# STM32H730 register map
File version: 1.8
CPU: CM7 r0p1, little endian, MPU, FPU, 4 interrupt priority bits
Registers are 32-bit, read-write, reset 0x0 unless marked. A register's access mark holds for its fields unless they carry their own. Offsets are from the block's base; [hi:lo] are bit positions; {n}, {i} and the like mark numbered series; 'fields as' and 'values as' point back to an identical list.

## OTFDEC1 — OTFDEC address block description
Base 0x5200B800
Same registers: OTFDEC2 0x5200BC00
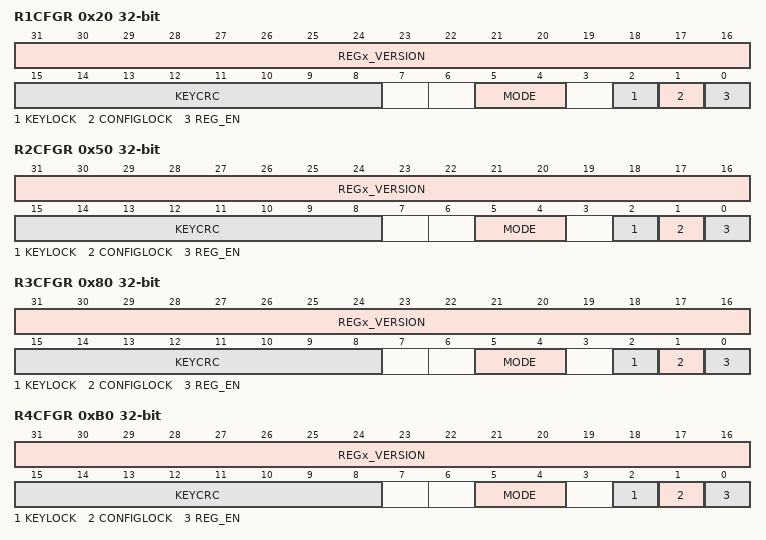
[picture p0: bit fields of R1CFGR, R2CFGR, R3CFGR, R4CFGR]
0x20 R1CFGR access per field — OTFDEC region 1 configuration register
  [31:16] REGx_VERSION rw — region firmware version This 16-bit bitfield must be correctly initialized before the region corresponding REG_EN bit is set in the RxCFGR register.
  [15:8] KEYCRC ro — region key 8-bit CRC When KEYLOCK=0, KEYCRC bitfield is automatically computed by hardware while loading the key of this region in this exact sequence: KEYR0 then KEYR1 then KEYR2 then finally KEYR3 (all written once). A new computation starts as soon as a new valid sequence is initiated, and KEYCRC is read as zero until a valid sequence is completed. When KEYLOCK=1, KEYCRC remains unchanged until the next reset. CRC computation is an 8-bit checksum using the standard CRC-8-CCITT algorithm X8 + X2 + X + 1 (according the convention). Source code is available in this manual. This field is read only. Note: CRC information is updated only after the last bit of the key has been written.
  [5:4] MODE rw — operating mode This bitfield selects the OTFDEC operating mode for this region: When MODE is not equal to 11 the standard AES encryption mode is activated. When either of the MODE bits are changed the region's key and associated CRC are zeroed.
  [2] KEYLOCK rw — region key lock This bitfield is set once, i.e. if this bit is set it can only be reset to '0' if the OTFDEC is reset.
  [1] CONFIGLOCK rw — region config lock This bit-field is set once, i.e. if this bit is set it can only be reset to '0' if OTFDEC is reset. Setting this bit forces KEYLOCK bit to '1'.
  [0] REG_EN rw — region on-the-fly decryption enable Note: When this bit is set region context (version, key, nonce) must be valid or garbage will be decrypted.
0x24 R1STARTADDR — OTFDEC region 1 start address register
  [31:0] REGx_START_ADDR — Region AXI start address This register must be written before the region corresponding REG_EN bit in the RxCFGR register is set. Writing this register while the region CONFIGLOCK bit in the RxCFGR register is set will be discarded. Note: When determining the region the first 12 bits (LSB) and the last 4 bits (MSB) are ignored. When this register is accessed in read the 4 MSB bits and the 12 LSB bits return zero.
0x28 R1ENDADDR reset 0xFFF — OTFDEC region 1 end address register
  [31:0] REGx_END_ADDR — Region AXI end address This register must be written before the region corresponding REG_EN bit in the RxCFGR register is set, and RxENDADDR must be strictly greater than RxSTARTADDR to be valid. Writing this register while the region CONFIGLOCK bit in the RxCFGR register is set will be discarded. Note: When determining the region the first 12 bits (LSB) and the last 4 bits (MSB) are ignored. When this register is accessed in read the 4 MSB bits returns zeros and the 12 LSB bits return ones.
0x2C R1NONCER0 — OTFDEC region 1 nonce register 0
  [31:0] REGx_NONCE — Region nonce, bits [31:0] This register must be written before the region corresponding REG_EN bit in the RxCFGR register is set. Writing this register while the region CONFIGLOCK bit in the RxCFGR register is set will be discarded.
{0x0+0x30*i} R{i}NONCER1 (i=1..4) — OTFDEC region {i} nonce register 1
  [31:0] REGx_NONCE — Region nonce, bits [63:32] Refer to the OTFDEC_RxNONCER0 register for description of the NONCE[63:0] bitfield.
{0x4+0x30*i} R{i}KEYR0 wo (i=1..4) — OTFDEC region {i} key register 0
  [31:0] REGx_KEY — Region key, bits [31:0] This register must be written before the region corresponding REG_EN bit in the RxCFGR register is set. Reading this register returns a zero value. Writing this register while the region CONFIGLOCK or KEYLOCK bit is set in the RxCFGR register will be discarded. Note: When application successfully changes MODE bits in RxCFGR register RxKEYR registers and associated KEYCRC are erased.
{0x8+0x30*i} R{i}KEYR1 wo (i=1..4) — OTFDEC region {i} key register 1
  [31:0] REGx_KEY — Region key, bits [63:32] Refer to the OTFDEC_RxKEYR0 register for description of the KEY[127:0] bitfield.
{0xC+0x30*i} R{i}KEYR2 wo (i=1..4) — OTFDEC region {i} key register 2
  [31:0] REGx_KEY — Region key, bits [95:64] Refer to the OTFDEC_RxKEYR0 register for description of the KEY[127:0] bitfield.
{0x10+0x30*i} R{i}KEYR3 wo (i=1..4) — OTFDEC region {i} key register 3
  [31:0] REGx_KEY — Region key, bits [127:96] Refer to the OTFDEC_RxKEYR0 register for description of the KEY[127:0] bitfield.
0x50 R2CFGR access per field — OTFDEC region 2 configuration register
  fields as R1CFGR
0x54 R2STARTADDR — OTFDEC region 2 start address register
  fields as R1STARTADDR
0x58 R2ENDADDR reset 0xFFF — OTFDEC region 2 end address register
  fields as R1ENDADDR
0x5C R2NONCER0 — OTFDEC region 2 nonce register 0
  fields as R1NONCER0
0x80 R3CFGR access per field — OTFDEC region 3 configuration register
  fields as R1CFGR
0x84 R3STARTADDR — OTFDEC region 3 start address register
  fields as R1STARTADDR
0x88 R3ENDADDR reset 0xFFF — OTFDEC region 3 end address register
  fields as R1ENDADDR
0x8C R3NONCER0 — OTFDEC region 3 nonce register 0
  fields as R1NONCER0
0xB0 R4CFGR access per field — OTFDEC region 4 configuration register
  fields as R1CFGR
0xB4 R4STARTADDR — OTFDEC region 4 start address register
  fields as R1STARTADDR
0xB8 R4ENDADDR reset 0xFFF — OTFDEC region 4 end address register
  fields as R1ENDADDR
0xBC R4NONCER0 — OTFDEC region 4 nonce register 0
  fields as R1NONCER0
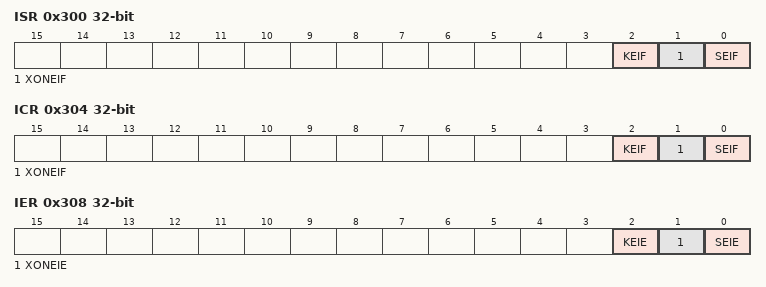
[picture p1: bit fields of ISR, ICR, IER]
0x300 ISR ro — OTFDEC interrupt status register
  [2] KEIF — Key Error Interrupt Flag status This bit is set by hardware and read only by application. Bit is set when a read access occurs on any encrypted region following the reset of the key registers by an abort event (tamper detection, unauthorized debugger connection, untrusted boot, RDP level regression). Bit is cleared when application sets in OTFDEC_ICR the corresponding bit to '1'. After KEIF is set any subsequent read to any enabled encrypted region returns a zeroed value. This state remains until OTFDEC keys are initialized again.
  [1] XONEIF — Execute-only execute-Never Error Interrupt Flag status This bit is set by hardware and read only by application. Bit is set when a read access and not an instruction fetch is detected on any encrypted region with MODE bits set to 00 or 11. It is also set when an instruction fetch and not a read access is detected on any encrypted region with MODE bits set to 01. Bit is cleared when application sets in OTFDEC_ICR the corresponding bit to '1'.
  [0] SEIF — Security Error Interrupt Flag status This bit is set by hardware and read only by application. Bit is set when at least one security error has been detected (illegal access to keys, illegal write on locked configuration). Bit is cleared when application sets in OTFDEC_ICR the corresponding bit to '1'.
0x304 ICR wo — OTFDEC interrupt clear register
  [2] KEIF — Key Error Interrupt Flag clear This bit is written by application, and always reads as 0. Note: Clearing KEIF does not solve the source of the problem (bad key registers). To be able to read or execute again any encrypted region, OTFDEC key registers must properly initialized, again.
  [1] XONEIF — Execute-only execute-Never Error Interrupt Flag clear This bit is written by application, and always reads as 0.
  [0] SEIF — Security Error Interrupt Flag clear This bit is written by application, and always reads as 0.
0x308 IER — OTFDEC interrupt enable register
  [2] KEIE — Key Error Interrupt Enable This bit is read and written by application. It controls the OTFDEC interrupt generation when KEIF flag status is set.
  [1] XONEIE — Execute-only execute-Never Error Interrupt Enable This bit is read and written by application. It controls the OTFDEC interrupt generation when XONEIF flag status is set.
  [0] SEIE — Security Error Interrupt Enable This bit is read and written by application. It controls the OTFDEC interrupt generation when SEIF flag status is set.
